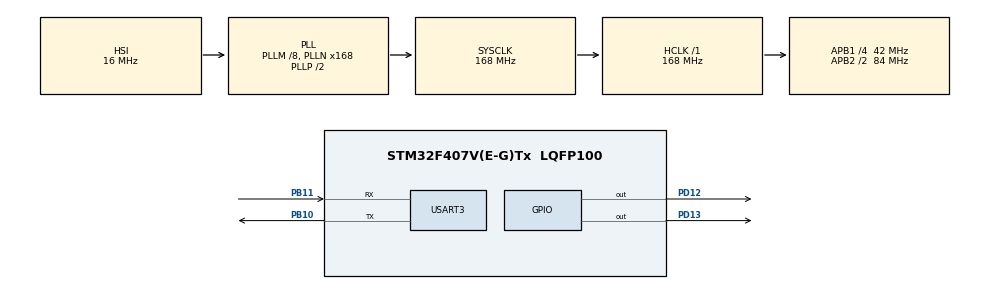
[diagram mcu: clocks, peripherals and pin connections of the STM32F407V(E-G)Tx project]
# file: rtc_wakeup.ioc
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FREERTOS.Tasks01=defaultTask,0,128,StartDefaultTask,Default
Mcu.Family=STM32F4
Mcu.Name=STM32F407V(E-G)Tx
Mcu.Package=LQFP100
NVIC.PriorityGroup=NVIC_PRIORITYGROUP_4
NVIC.RTC_WKUP_IRQn=true\:0\:0\:false\:false\:true\:false
NVIC.TIM1_UP_TIM10_IRQn=true\:0\:0\:false\:false\:true\:false
NVIC.TimeBase=TIM1_UP_TIM10_IRQn
NVIC.TimeBaseIP=TIM1
PA13.Mode=Serial_Wire
PA13.Signal=SYS_JTMS-SWDIO
PA14.Mode=Serial_Wire
PA14.Signal=SYS_JTCK-SWCLK
PB10.Mode=Asynchronous
PB10.Signal=USART3_TX
PB11.Mode=Asynchronous
PB11.Signal=USART3_RX
PC14-OSC32_IN.Mode=LSE-External-Oscillator
PC14-OSC32_IN.Signal=RCC_OSC32_IN
PC15-OSC32_OUT.Mode=LSE-External-Oscillator
PC15-OSC32_OUT.Signal=RCC_OSC32_OUT
PD12.Signal=GPIO_Output
PD13.Signal=GPIO_Output
PH0-OSC_IN.Mode=HSE-External-Oscillator
PH0-OSC_IN.Signal=RCC_OSC_IN
PH1-OSC_OUT.Mode=HSE-External-Oscillator
PH1-OSC_OUT.Signal=RCC_OSC_OUT
ProjectManager.HeapSize=0x200
ProjectManager.StackSize=0x400
ProjectManager.TargetToolchain=MDK-ARM V5
RCC.48MHZClocksFreq_Value=84000000
RCC.AHBFreq_Value=168000000
RCC.APB1CLKDivider=RCC_HCLK_DIV4
RCC.APB1Freq_Value=42000000
RCC.APB1TimFreq_Value=84000000
RCC.APB2CLKDivider=RCC_HCLK_DIV2
RCC.APB2Freq_Value=84000000
RCC.APB2TimFreq_Value=168000000
RCC.CortexFreq_Value=168000000
RCC.HCLKFreq_Value=168000000
RCC.HSE_VALUE=8000000
RCC.HSI_VALUE=16000000
RCC.PLLM=8
RCC.PLLN=168
RCC.SYSCLKFreq_VALUE=168000000
RCC.SYSCLKSource=RCC_SYSCLKSOURCE_PLLCLK
RCC.VCOOutputFreq_Value=336000000
RTC.WakeUpCounter=20000
VP_FREERTOS_VS_ENABLE.Mode=Enabled
VP_RTC_VS_RTC_WakeUp_intern.Mode=WakeUp
VP_SYS_VS_tim1.Mode=TIM1
board=rtc_wakeup

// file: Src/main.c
/**
  ******************************************************************************
  * File Name          : main.c
  * Description        : Main program body
  ******************************************************************************
  *
  * COPYRIGHT(c) 2017 STMicroelectronics
  *
  * Redistribution and use in source and binary forms, with or without modification,
  * are permitted provided that the following conditions are met:
  *   1. Redistributions of source code must retain the above copyright notice,
  *      this list of conditions and the following disclaimer.
  *   2. Redistributions in binary form must reproduce the above copyright notice,
  *      this list of conditions and the following disclaimer in the documentation
  *      and/or other materials provided with the distribution.
  *   3. Neither the name of STMicroelectronics nor the names of its contributors
  *      may be used to endorse or promote products derived from this software
  *      without specific prior written permission.
  *
  * THIS SOFTWARE IS PROVIDED BY THE COPYRIGHT HOLDERS AND CONTRIBUTORS "AS IS"
  * AND ANY EXPRESS OR IMPLIED WARRANTIES, INCLUDING, BUT NOT LIMITED TO, THE
  * IMPLIED WARRANTIES OF MERCHANTABILITY AND FITNESS FOR A PARTICULAR PURPOSE ARE
  * DISCLAIMED. IN NO EVENT SHALL THE COPYRIGHT HOLDER OR CONTRIBUTORS BE LIABLE
  * FOR ANY DIRECT, INDIRECT, INCIDENTAL, SPECIAL, EXEMPLARY, OR CONSEQUENTIAL
  * DAMAGES (INCLUDING, BUT NOT LIMITED TO, PROCUREMENT OF SUBSTITUTE GOODS OR
  * SERVICES; LOSS OF USE, DATA, OR PROFITS; OR BUSINESS INTERRUPTION) HOWEVER
  * CAUSED AND ON ANY THEORY OF LIABILITY, WHETHER IN CONTRACT, STRICT LIABILITY,
  * OR TORT (INCLUDING NEGLIGENCE OR OTHERWISE) ARISING IN ANY WAY OUT OF THE USE
  * OF THIS SOFTWARE, EVEN IF ADVISED OF THE POSSIBILITY OF SUCH DAMAGE.
  *
  ******************************************************************************
  */
#include "stm32f4xx_hal.h"
#include "cmsis_os.h"

RTC_HandleTypeDef hrtc;

UART_HandleTypeDef huart3;

osThreadId defaultTaskHandle;

/* USER CODE BEGIN PV */
/* Private variables ---------------------------------------------------------*/

/* USER CODE END PV */

void SystemClock_Config(void);
void Error_Handler(void);
static void MX_GPIO_Init(void);
static void MX_RTC_Init(void);
static void MX_USART3_UART_Init(void);
void StartDefaultTask(void const * argument);

/* USER CODE BEGIN PFP */
/* Private function prototypes -----------------------------------------------*/

/* USER CODE END PFP */

int main(void)
{

  /* MCU Configuration----------------------------------------------------------*/

  /* Reset of all peripherals, Initializes the Flash interface and the Systick. */
  HAL_Init();

  /* Configure the system clock */
  SystemClock_Config();

  /* Initialize all configured peripherals */
  MX_GPIO_Init();
  MX_RTC_Init();
  MX_USART3_UART_Init();

  /* Create the thread(s) */
  /* definition and creation of defaultTask */
  osThreadDef(defaultTask, StartDefaultTask, osPriorityNormal, 0, 128);
  defaultTaskHandle = osThreadCreate(osThread(defaultTask), NULL);

  /* Start scheduler */
  osKernelStart();

  /* We should never get here as control is now taken by the scheduler */

  /* Infinite loop */
  while (1)
  {

  }

}

/** System Clock Configuration
*/
void SystemClock_Config(void)
{

  RCC_OscInitTypeDef RCC_OscInitStruct;
  RCC_ClkInitTypeDef RCC_ClkInitStruct;
  RCC_PeriphCLKInitTypeDef PeriphClkInitStruct;

  __HAL_RCC_PWR_CLK_ENABLE();

  __HAL_PWR_VOLTAGESCALING_CONFIG(PWR_REGULATOR_VOLTAGE_SCALE1);

  RCC_OscInitStruct.OscillatorType = RCC_OSCILLATORTYPE_HSI|RCC_OSCILLATORTYPE_LSI;
  RCC_OscInitStruct.HSIState = RCC_HSI_ON;
  RCC_OscInitStruct.HSICalibrationValue = 16;
  RCC_OscInitStruct.LSIState = RCC_LSI_ON;
  RCC_OscInitStruct.PLL.PLLState = RCC_PLL_ON;
  RCC_OscInitStruct.PLL.PLLSource = RCC_PLLSOURCE_HSI;
  RCC_OscInitStruct.PLL.PLLM = 8;
  RCC_OscInitStruct.PLL.PLLN = 168;
  RCC_OscInitStruct.PLL.PLLP = RCC_PLLP_DIV2;
  RCC_OscInitStruct.PLL.PLLQ = 4;
  if (HAL_RCC_OscConfig(&RCC_OscInitStruct) != HAL_OK)
  {
    Error_Handler();
  }

  RCC_ClkInitStruct.ClockType = RCC_CLOCKTYPE_HCLK|RCC_CLOCKTYPE_SYSCLK
                              |RCC_CLOCKTYPE_PCLK1|RCC_CLOCKTYPE_PCLK2;
  RCC_ClkInitStruct.SYSCLKSource = RCC_SYSCLKSOURCE_PLLCLK;
  RCC_ClkInitStruct.AHBCLKDivider = RCC_SYSCLK_DIV1;
  RCC_ClkInitStruct.APB1CLKDivider = RCC_HCLK_DIV4;
  RCC_ClkInitStruct.APB2CLKDivider = RCC_HCLK_DIV2;
  if (HAL_RCC_ClockConfig(&RCC_ClkInitStruct, FLASH_LATENCY_5) != HAL_OK)
  {
    Error_Handler();
  }

  PeriphClkInitStruct.PeriphClockSelection = RCC_PERIPHCLK_RTC;
  PeriphClkInitStruct.RTCClockSelection = RCC_RTCCLKSOURCE_LSI;
  if (HAL_RCCEx_PeriphCLKConfig(&PeriphClkInitStruct) != HAL_OK)
  {
    Error_Handler();
  }

  HAL_SYSTICK_Config(HAL_RCC_GetHCLKFreq()/1000);

  HAL_SYSTICK_CLKSourceConfig(SYSTICK_CLKSOURCE_HCLK);

  /* SysTick_IRQn interrupt configuration */
  HAL_NVIC_SetPriority(SysTick_IRQn, 15, 0);
}

/* RTC init function */
static void MX_RTC_Init(void)
{

  RTC_TimeTypeDef sTime;
  RTC_DateTypeDef sDate;

    /**Initialize RTC and set the Time and Date
    */
  hrtc.Instance = RTC;
  hrtc.Init.HourFormat = RTC_HOURFORMAT_24;
  hrtc.Init.AsynchPrediv = 127;
  hrtc.Init.SynchPrediv = 255;
  hrtc.Init.OutPut = RTC_OUTPUT_DISABLE;
  hrtc.Init.OutPutPolarity = RTC_OUTPUT_POLARITY_HIGH;
  hrtc.Init.OutPutType = RTC_OUTPUT_TYPE_OPENDRAIN;
  if (HAL_RTC_Init(&hrtc) != HAL_OK)
  {
    Error_Handler();
  }

  sTime.Hours = 0x0;
  sTime.Minutes = 0x0;
  sTime.Seconds = 0x0;
  sTime.DayLightSaving = RTC_DAYLIGHTSAVING_NONE;
  sTime.StoreOperation = RTC_STOREOPERATION_RESET;
  if (HAL_RTC_SetTime(&hrtc, &sTime, RTC_FORMAT_BCD) != HAL_OK)
  {
    Error_Handler();
  }

  sDate.WeekDay = RTC_WEEKDAY_MONDAY;
  sDate.Month = RTC_MONTH_JANUARY;
  sDate.Date = 0x1;
  sDate.Year = 0x0;

  if (HAL_RTC_SetDate(&hrtc, &sDate, RTC_FORMAT_BCD) != HAL_OK)
  {
    Error_Handler();
  }

    /**Enable the WakeUp
    */
  if (HAL_RTCEx_SetWakeUpTimer_IT(&hrtc, 20000, RTC_WAKEUPCLOCK_RTCCLK_DIV16) != HAL_OK)
  {
    Error_Handler();
  }

}

/* USART3 init function */
static void MX_USART3_UART_Init(void)
{

  huart3.Instance = USART3;
  huart3.Init.BaudRate = 115200;
  huart3.Init.WordLength = UART_WORDLENGTH_8B;
  huart3.Init.StopBits = UART_STOPBITS_1;
  huart3.Init.Parity = UART_PARITY_NONE;
  huart3.Init.Mode = UART_MODE_TX_RX;
  huart3.Init.HwFlowCtl = UART_HWCONTROL_NONE;
  huart3.Init.OverSampling = UART_OVERSAMPLING_16;
  if (HAL_UART_Init(&huart3) != HAL_OK)
  {
    Error_Handler();
  }

}

/** Configure pins as
        * Analog
        * Input
        * Output
        * EVENT_OUT
        * EXTI
*/
static void MX_GPIO_Init(void)
{

  GPIO_InitTypeDef GPIO_InitStruct;

  /* GPIO Ports Clock Enable */
  __HAL_RCC_GPIOC_CLK_ENABLE();
  __HAL_RCC_GPIOH_CLK_ENABLE();
  __HAL_RCC_GPIOB_CLK_ENABLE();
  __HAL_RCC_GPIOD_CLK_ENABLE();
  __HAL_RCC_GPIOA_CLK_ENABLE();

  /*Configure GPIO pin Output Level */
  HAL_GPIO_WritePin(GPIOD, GPIO_PIN_12|GPIO_PIN_13, GPIO_PIN_RESET);

  /*Configure GPIO pins : PD12 PD13 */
  GPIO_InitStruct.Pin = GPIO_PIN_12|GPIO_PIN_13;
  GPIO_InitStruct.Mode = GPIO_MODE_OUTPUT_PP;
  GPIO_InitStruct.Pull = GPIO_NOPULL;
  GPIO_InitStruct.Speed = GPIO_SPEED_FREQ_LOW;
  HAL_GPIO_Init(GPIOD, &GPIO_InitStruct);

}

/* StartDefaultTask function */
void StartDefaultTask(void const * argument)
{

  /* USER CODE BEGIN 5 */
  /* Infinite loop */
  for(;;)
  {
		__HAL_PWR_CLEAR_FLAG(PWR_FLAG_WU);
		HAL_UART_Transmit(&huart3, (uint8_t *)"starting\n", 10, 100);
		for(int i=0;i<5;i++)
		{
			HAL_UART_Transmit(&huart3, (uint8_t *)(48+i), 1, 100);
			osDelay(1000);
		}
		HAL_PWR_EnterSTANDBYMode();
    osDelay(1);
  }
  /* USER CODE END 5 */
}

void HAL_TIM_PeriodElapsedCallback(TIM_HandleTypeDef *htim)
{
  if (htim->Instance == TIM1) {
    HAL_IncTick();
  }
}

void Error_Handler(void)
{
  while(1)
  {
  }
}

/************************ (C) COPYRIGHT STMicroelectronics *****END OF FILE****/
